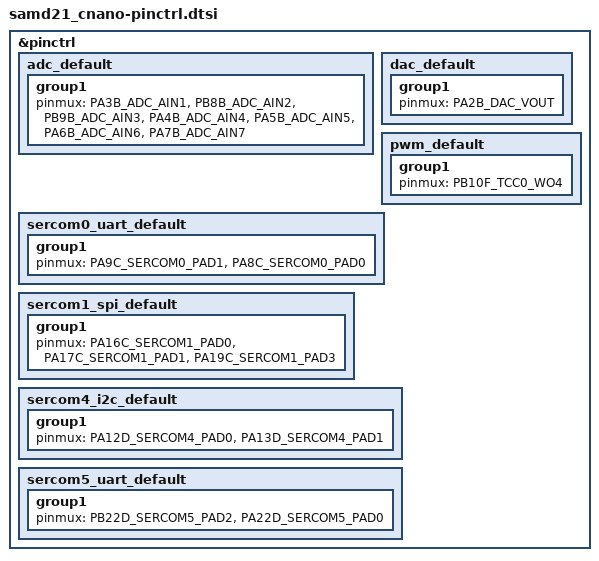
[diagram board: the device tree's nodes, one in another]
/*
 * SPDX-License-Identifier: Apache-2.0
 */

#include <dt-bindings/pinctrl/samd21-da1gXabcd-pinctrl.h>

&pinctrl {
	adc_default: adc_default {
		group1 {
			pinmux = <PA3B_ADC_AIN1>,
				 <PB8B_ADC_AIN2>,
				 <PB9B_ADC_AIN3>,
				 <PA4B_ADC_AIN4>,
				 <PA5B_ADC_AIN5>,
				 <PA6B_ADC_AIN6>,
				 <PA7B_ADC_AIN7>;
		};
	};

	dac_default: dac_default {
		group1 {
			pinmux = <PA2B_DAC_VOUT>;
		};
	};

	pwm_default: pwm_default {
		group1 {
			pinmux = <PB10F_TCC0_WO4>;
		};
	};

	sercom0_uart_default: sercom0_uart_default {
		group1 {
			pinmux = <PA9C_SERCOM0_PAD1>,
				 <PA8C_SERCOM0_PAD0>;
		};
	};

	sercom1_spi_default: sercom1_spi_default {
		group1 {
			pinmux = <PA16C_SERCOM1_PAD0>,
				 <PA17C_SERCOM1_PAD1>,
				 <PA19C_SERCOM1_PAD3>;
		};
	};

	sercom4_i2c_default: sercom4_i2c_default {
		group1 {
			pinmux = <PA12D_SERCOM4_PAD0>,
				 <PA13D_SERCOM4_PAD1>;
		};
	};

	sercom5_uart_default: sercom5_uart_default {
		group1 {
			pinmux = <PB22D_SERCOM5_PAD2>,
				 <PA22D_SERCOM5_PAD0>;
		};
	};
};
